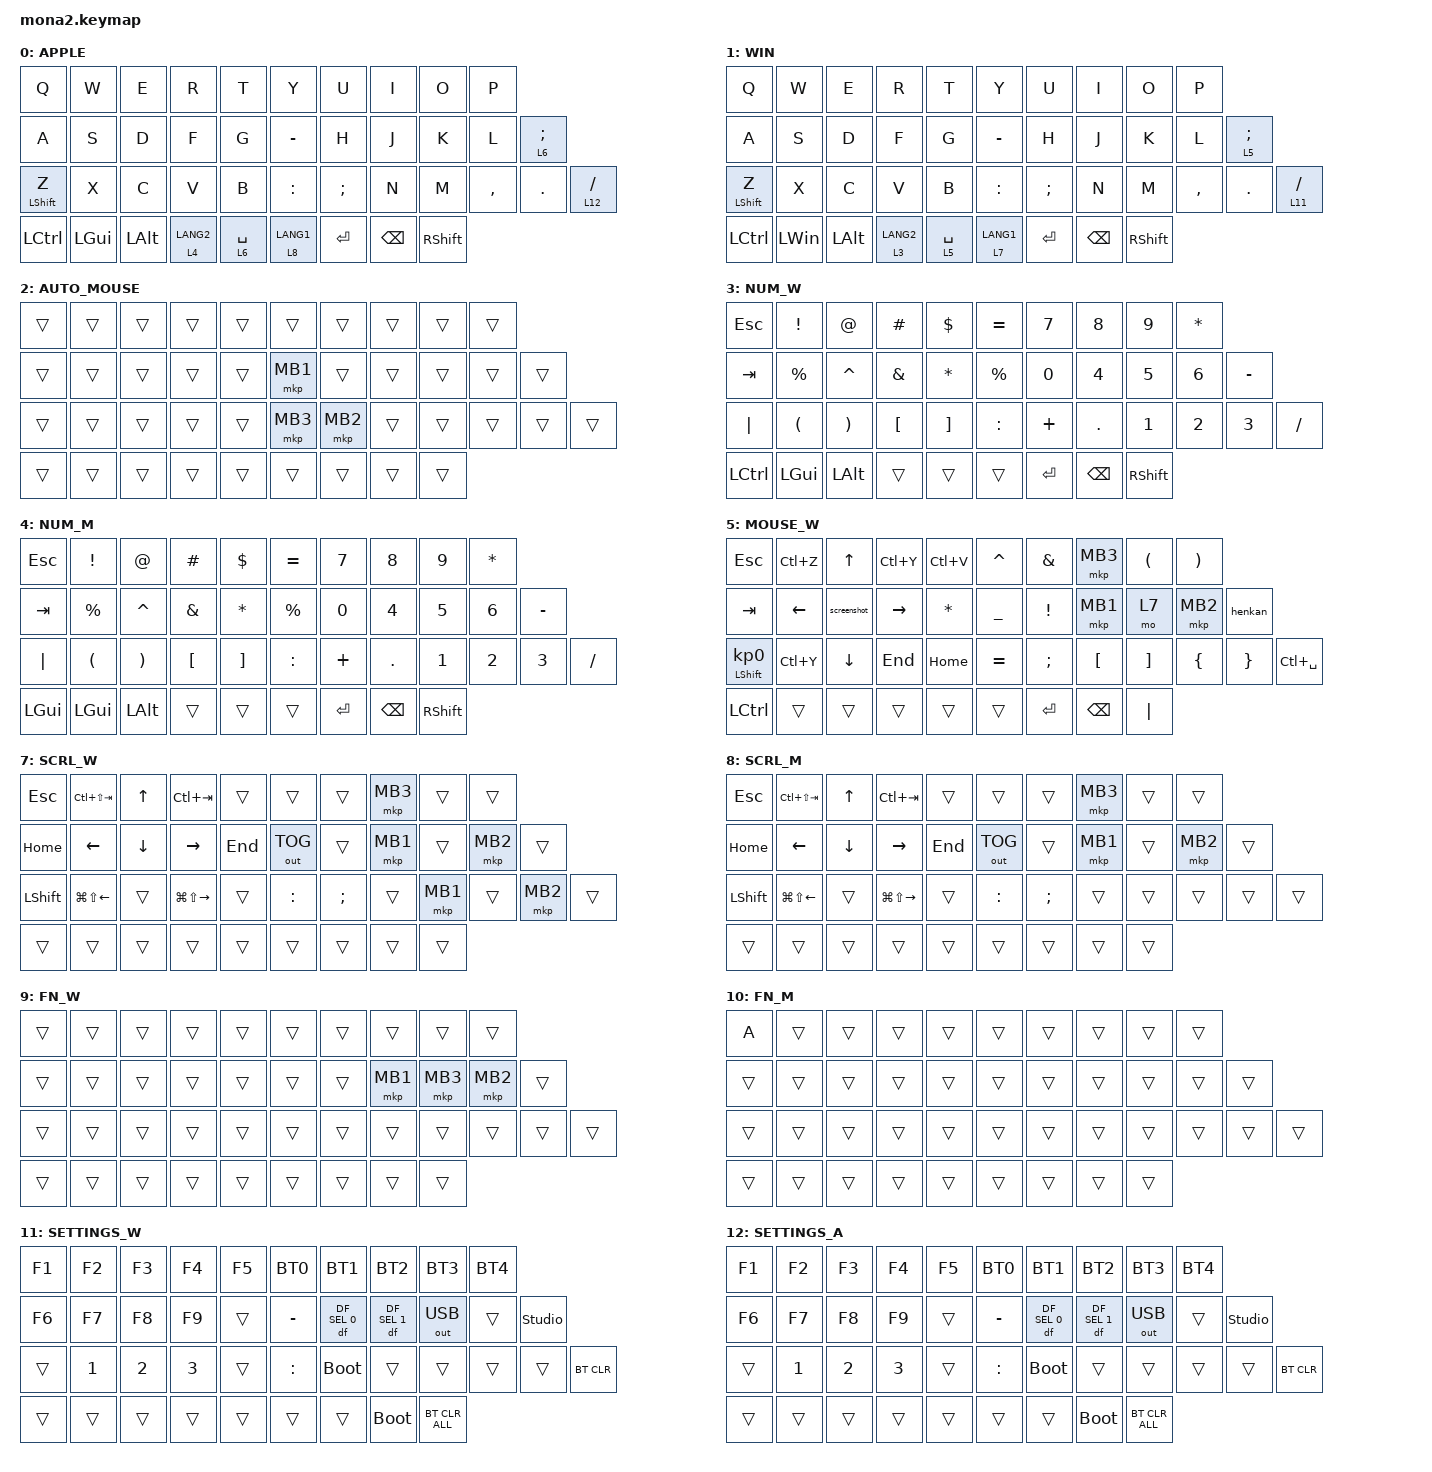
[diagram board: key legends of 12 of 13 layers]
#include <input/processors.dtsi>
#include <dt-bindings/zmk/input_transform.h>
#include <zephyr/dt-bindings/input/input-event-codes.h>
#include <behaviors.dtsi>
#include <behaviors/default_layer.dtsi>
#include <behaviors/runtime-sensor-rotate.dtsi>
#include <dt-bindings/zmk_behavior_default_layer/default_layer.h>
#include <dt-bindings/zmk/bt.h>
#include <dt-bindings/zmk/keys.h>
#include <dt-bindings/zmk/outputs.h>
#include <dt-bindings/zmk/pointing.h>

/* ZMK 側で 10 が定義済みなので警告回避のため一旦 undef */
#undef ZMK_POINTING_DEFAULT_SCRL_VAL
#define ZMK_POINTING_DEFAULT_SCRL_VAL 100

&mt {
flavor = "balanced";
quick-tap-ms = <0>;
};

&lt {
quick-tap-ms = <200>;
flavor = "balanced";
};

&msc {
delay-ms = <0>;
time-to-max-speed-ms = <0>;
acceleration-exponent = <0>;
};

/ {
combos {
compatible = "zmk,combos";

layer4_ESC {
bindings = <&lt 2 ESC>;
key-positions = <39 38>;
};

tab {
bindings = <&kp TAB>;
key-positions = <11 12>;
};
};

macros {
BT0: BT0 {
compatible = "zmk,behavior-macro";
#binding-cells = <0>;
bindings = <&bt BT_SEL 0 &out OUT_BLE>;

label = "BT0";
};

BT1: BT1 {
compatible = "zmk,behavior-macro";
#binding-cells = <0>;
bindings = <&bt BT_SEL 1 &out OUT_BLE>;

label = "BT1";
};

BT2: BT2 {
compatible = "zmk,behavior-macro";
#binding-cells = <0>;
bindings = <&bt BT_SEL 2 &out OUT_BLE>;
label = "BT2";
};

BT3: BT3 {
compatible = "zmk,behavior-macro";
#binding-cells = <0>;
bindings = <&bt BT_SEL 3 &out OUT_BLE>;
label = "BT3";
};

BT4: BT4 {
compatible = "zmk,behavior-macro";
#binding-cells = <0>;
bindings = <&bt BT_SEL 4 &out OUT_BLE>;
label = "BT4";
};

screenshot: screenshot {
compatible = "zmk,behavior-macro";
#binding-cells = <0>;
bindings =
<&macro_press>,
<&kp LEFT_GUI &kp RSHIFT>,
<&macro_wait_time 20>,
<&macro_tap>,
<&kp S>,
<&macro_release>,
<&kp LEFT_GUI &kp RSHIFT>;

label = "SCREENSHOT";
};

henkan: henkan {
compatible = "zmk,behavior-macro";
#binding-cells = <0>;
bindings =
<&macro_press>,
<&kp LEFT_ALT>,
<&macro_wait_time 20>,
<&macro_tap>,
<&kp GRAVE>,
<&macro_release>,
<&kp LEFT_ALT>;

label = "HENKAN";
};
};

behaviors {
tp_repeat_mo1: tp_repeat_mo1 {
compatible = "zmk,behavior-hold-tap";
label = "TP_REPEAT_MO1";
bindings = <&mo>, <&key_repeat>;

#binding-cells = <2>;
tapping-term-ms = <200>;
};

// エンコーダ用 runtime-configurable sensor rotate
// デフォルトはスクロール (cw=SCRL_DOWN, ccw=SCRL_UP)
// DYA Studio Web UI から レイヤーごとに cw/ccw の binding を
// kp C_VOL_UP/DN や kp LEFT/RIGHT などへ動的変更可能
rsr_default: rsr_default {
compatible = "zmk,behavior-runtime-sensor-rotate";
#sensor-binding-cells = <0>;
tap-ms = <16>;
cw-binding = <&msc SCRL_DOWN>;
ccw-binding = <&msc SCRL_UP>;
};

zfold: zfold {
compatible = "zmk,behavior-hold-tap";
label = "ZFOLD";
bindings = <&kp>, <&kp>;

#binding-cells = <2>;
tapping-term-ms = <300>;
flavor = "hold-preferred";
quick-tap-ms = <150>;
hold-while-undecided;
};

zfoldZ: zfoldZ {
compatible = "zmk,behavior-tap-dance";
label = "ZFOLDZ";
#binding-cells = <0>;
bindings = <&zfold LEFT_SHIFT Z>, <&kp LS(Z)>;
};
};

keymap {
compatible = "zmk,keymap";

apple_layer {
display-name = "APPLE";
bindings = <
&kp Q &kp W &kp E &kp R &kp T &kp Y &kp U &kp I &kp O &kp P
&kp A &kp S &kp D &kp F &kp G &kp MINUS &kp H &kp J &kp K &kp L &lt 6 SEMICOLON
&mt LEFT_SHIFT Z &kp X &kp C &kp V &kp B &kp COLON &kp SEMICOLON &kp N &kp M &kp COMMA &kp DOT &lt 12 SLASH
&kp LCTRL &kp LEFT_GUI &kp LEFT_ALT &lt 4 LANG2 &lt 6 SPACE &lt 8 LANG1 &kp ENTER &kp BACKSPACE &kp RIGHT_SHIFT
>;

sensor-bindings =
<&rsr_default>,
<&inc_dec_kp C_VOL_DN C_VOL_UP>;
};

win_layer {
display-name = "WIN";
bindings = <
&kp Q &kp W &kp E &kp R &kp T &kp Y &kp U &kp I &kp O &kp P
&kp A &kp S &kp D &kp F &kp G &kp MINUS &kp H &kp J &kp K &kp L &lt 5 SEMICOLON
&mt LEFT_SHIFT Z &kp X &kp C &kp V &kp B &kp COLON &kp SEMICOLON &kp N &kp M &kp COMMA &kp DOT &lt 11 SLASH
&kp LCTRL &kp LEFT_WIN &kp LEFT_ALT &lt 3 LANG2 &lt 5 SPACE &lt 7 LANG1 &kp ENTER &kp BACKSPACE &kp RIGHT_SHIFT
>;

sensor-bindings =
<&rsr_default>,
<&inc_dec_kp C_VOL_DN C_VOL_UP>;
};

auto_mouse {
display-name = "AUTO_MOUSE";
bindings = <
&trans &trans &trans &trans &trans &trans &trans &trans &trans &trans
&trans &trans &trans &trans &trans &mkp MB1 &trans &trans &trans &trans &trans
&trans &trans &trans &trans &trans &mkp MB3 &mkp MB2 &trans &trans &trans &trans &trans
&trans &trans &trans &trans &trans &trans &trans &trans &trans
>;
};

num_win {
display-name = "NUM_W";
bindings = <
&kp ESCAPE &kp EXCLAMATION &kp AT_SIGN &kp HASH &kp DOLLAR &kp EQUAL &kp NUMBER_7 &kp NUMBER_8 &kp NUMBER_9 &kp ASTERISK
&kp TAB &kp PERCENT &kp CARET &kp AMPERSAND &kp ASTERISK &kp PERCENT &kp NUMBER_0 &kp NUMBER_4 &kp NUMBER_5 &kp NUMBER_6 &kp MINUS
&kp PIPE &kp LEFT_PARENTHESIS &kp RIGHT_PARENTHESIS &kp LEFT_BRACKET &kp RIGHT_BRACKET &kp COLON &kp PLUS &kp DOT &kp NUMBER_1 &kp NUMBER_2 &kp NUMBER_3 &kp SLASH
&kp LCTRL &kp LEFT_GUI &kp LEFT_ALT &trans &trans &trans &kp ENTER &kp BACKSPACE &kp RIGHT_SHIFT
>;

sensor-bindings = <&rsr_default>;
};

num_mac {
display-name = "NUM_M";
bindings = <
&kp ESCAPE &kp EXCLAMATION &kp AT_SIGN &kp HASH &kp DOLLAR &kp EQUAL &kp NUMBER_7 &kp NUMBER_8 &kp NUMBER_9 &kp ASTERISK
&kp TAB &kp PERCENT &kp CARET &kp AMPERSAND &kp ASTERISK &kp PERCENT &kp NUMBER_0 &kp NUMBER_4 &kp NUMBER_5 &kp NUMBER_6 &kp MINUS
&kp PIPE &kp LEFT_PARENTHESIS &kp RIGHT_PARENTHESIS &kp LEFT_BRACKET &kp RIGHT_BRACKET &kp COLON &kp PLUS &kp DOT &kp NUMBER_1 &kp NUMBER_2 &kp NUMBER_3 &kp SLASH
&kp LEFT_GUI &kp LEFT_GUI &kp LEFT_ALT &trans &trans &trans &kp ENTER &kp BACKSPACE &kp RIGHT_SHIFT
>;

sensor-bindings = <&rsr_default>;
};

mouse_win {
display-name = "MOUSE_W";
bindings = <
&kp ESCAPE &kp LC(Z) &kp UP_ARROW &kp LC(Y) &kp LC(V) &kp CARET &kp AMPERSAND &mkp MB3 &kp LEFT_PARENTHESIS &kp RIGHT_PARENTHESIS
&kp TAB &kp LEFT_ARROW &screenshot &kp RIGHT_ARROW &kp ASTERISK &kp UNDERSCORE &kp EXCLAMATION &mkp MB1 &mo 7 &mkp MB2 &henkan
&mt LEFT_SHIFT KP_NUMBER_0 &kp LC(Y) &kp DOWN_ARROW &kp END &kp HOME &kp EQUAL &kp SEMICOLON &kp LEFT_BRACKET &kp RIGHT_BRACKET &kp LEFT_BRACE &kp RIGHT_BRACE &kp LC(SPACE)
&kp LCTRL &trans &trans &trans &trans &trans &kp ENTER &kp BACKSPACE &kp PIPE
>;

sensor-bindings = <&rsr_default>;
};

mouse_mac {
display-name = "MOUSE_M";
bindings = <
&kp ESCAPE &kp LG(Z) &kp UP_ARROW &kp LG(LS(Z)) &kp LG(V) &kp CARET &kp AMPERSAND &mkp MB3 &kp LEFT_PARENTHESIS &kp RIGHT_PARENTHESIS
&kp TAB &kp LEFT_ARROW &kp LG(LC(LS(NUMBER_4))) &kp RIGHT_ARROW &kp LG(A) &kp UNDERSCORE &kp EXCLAMATION &mkp MB1 &mo 8 &mkp MB2 &kp LC(SPACE)
&mt LEFT_SHIFT KP_NUMBER_0 &kp LG(LC(Z)) &kp DOWN_ARROW &kp LG(RIGHT) &kp LG(LEFT) &kp EQUAL &kp SEMICOLON &kp LEFT_BRACKET &kp RIGHT_BRACKET &kp LEFT_BRACE &kp RIGHT_BRACE &kp LC(SPACE)
&kp LCTRL &trans &trans &trans &trans &trans &kp ENTER &kp BACKSPACE &kp PIPE
>;

sensor-bindings = <&rsr_default>;
};

scroll_win {
display-name = "SCRL_W";
bindings = <
&kp ESCAPE &kp LC(LS(TAB)) &kp UP_ARROW &kp LC(TAB) &trans &trans &trans &mkp MB3 &trans &trans
&kp HOME &kp LEFT_ARROW &kp DOWN_ARROW &kp RIGHT_ARROW &kp END &out OUT_TOG &trans &mkp MB1 &trans &mkp MB2 &trans
&kp LEFT_SHIFT &kp LG(LS(LEFT_ARROW)) &trans &kp LG(LS(RIGHT_ARROW)) &trans &kp COLON &kp SEMICOLON &trans &mkp MB1 &trans &mkp MB2 &trans
&trans &trans &trans &trans &trans &trans &trans &trans &trans
>;

sensor-bindings = <&rsr_default>;
};

scroll_mac {
display-name = "SCRL_M";
bindings = <
&kp ESCAPE &kp LC(LS(TAB)) &kp UP_ARROW &kp LC(TAB) &trans &trans &trans &mkp MB3 &trans &trans
&kp HOME &kp LEFT_ARROW &kp DOWN_ARROW &kp RIGHT_ARROW &kp END &out OUT_TOG &trans &mkp MB1 &trans &mkp MB2 &trans
&kp LEFT_SHIFT &kp LG(LS(LEFT_ARROW)) &trans &kp LG(LS(RIGHT_ARROW)) &trans &kp COLON &kp SEMICOLON &trans &trans &trans &trans &trans
&trans &trans &trans &trans &trans &trans &trans &trans &trans
>;

sensor-bindings = <&rsr_default>;
};

function_win {
display-name = "FN_W";
bindings = <
&trans &trans &trans &trans &trans &trans &trans &trans &trans &trans
&trans &trans &trans &trans &trans &trans &trans &mkp MB1 &mkp MB3 &mkp MB2 &trans
&trans &trans &trans &trans &trans &trans &trans &trans &trans &trans &trans &trans
&trans &trans &trans &trans &trans &trans &trans &trans &trans
>;
};

function_mac {
display-name = "FN_M";
bindings = <
&kp A &trans &trans &trans &trans &trans &trans &trans &trans &trans
&trans &trans &trans &trans &trans &trans &trans &trans &trans &trans &trans
&trans &trans &trans &trans &trans &trans &trans &trans &trans &trans &trans &trans
&trans &trans &trans &trans &trans &trans &trans &trans &trans
>;
};

ble_win {
display-name = "SETTINGS_W";
bindings = <
&kp F1 &kp F2 &kp F3 &kp F4 &kp F5 &BT0 &BT1 &BT2 &BT3 &BT4
&kp F6 &kp F7 &kp F8 &kp F9 &trans &kp MINUS &df DF_SEL 0 &df DF_SEL 1 &out OUT_USB &trans &studio_unlock
&trans &kp NUMBER_1 &kp NUMBER_2 &kp NUMBER_3 &trans &kp COLON &bootloader &trans &trans &trans &trans &bt BT_CLR
&trans &trans &trans &trans &trans &trans &trans &bootloader &bt BT_CLR_ALL
>;
};

ble_mac {
display-name = "SETTINGS_A";
bindings = <
&kp F1 &kp F2 &kp F3 &kp F4 &kp F5 &BT0 &BT1 &BT2 &BT3 &BT4
&kp F6 &kp F7 &kp F8 &kp F9 &trans &kp MINUS &df DF_SEL 0 &df DF_SEL 1 &out OUT_USB &trans &studio_unlock
&trans &kp NUMBER_1 &kp NUMBER_2 &kp NUMBER_3 &trans &kp COLON &bootloader &trans &trans &trans &trans &bt BT_CLR
&trans &trans &trans &trans &trans &trans &trans &bootloader &bt BT_CLR_ALL
>;
};
};
};
